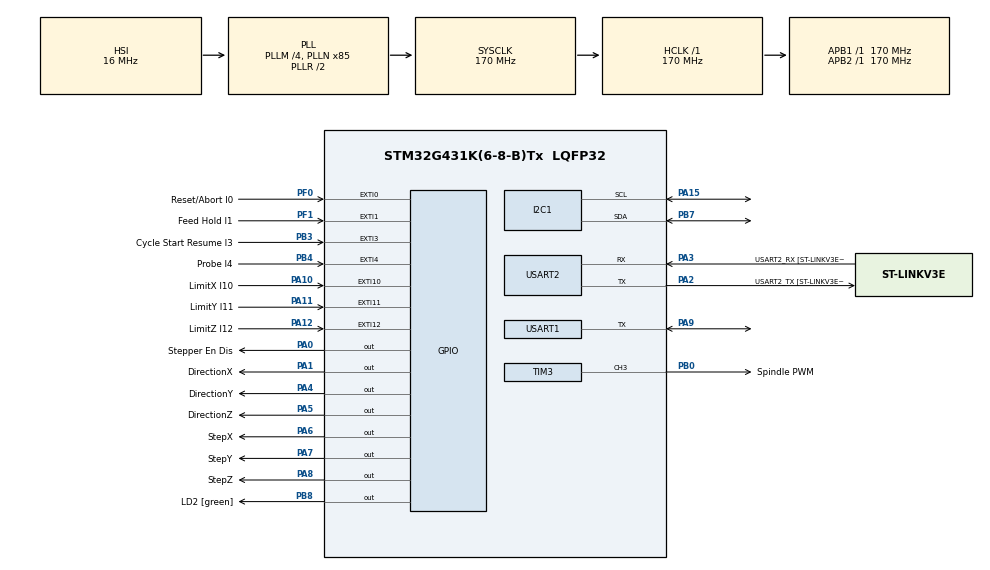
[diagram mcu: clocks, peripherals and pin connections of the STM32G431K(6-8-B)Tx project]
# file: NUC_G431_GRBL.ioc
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Dma.Request0=USART2_TX
Dma.USART2_TX.0.Direction=DMA_MEMORY_TO_PERIPH
Dma.USART2_TX.0.EventEnable=DISABLE
Dma.USART2_TX.0.Instance=DMA1_Channel2
Dma.USART2_TX.0.MemDataAlignment=DMA_MDATAALIGN_BYTE
Dma.USART2_TX.0.MemInc=DMA_MINC_ENABLE
Dma.USART2_TX.0.Mode=DMA_CIRCULAR
Dma.USART2_TX.0.PeriphDataAlignment=DMA_PDATAALIGN_BYTE
Dma.USART2_TX.0.PeriphInc=DMA_PINC_DISABLE
Dma.USART2_TX.0.Polarity=HAL_DMAMUX_REQ_GEN_RISING
Dma.USART2_TX.0.Priority=DMA_PRIORITY_LOW
Dma.USART2_TX.0.RequestNumber=1
Dma.USART2_TX.0.SignalID=NONE
Dma.USART2_TX.0.SyncEnable=DISABLE
Dma.USART2_TX.0.SyncPolarity=HAL_DMAMUX_SYNC_NO_EVENT
Dma.USART2_TX.0.SyncRequestNumber=1
Dma.USART2_TX.0.SyncSignalID=NONE
I2C1.Analog_Filter=I2C_ANALOGFILTER_ENABLE
I2C1.CustomTiming=Disabled
I2C1.I2C_Coeff_DF=0
I2C1.I2C_Fall_Time=0
I2C1.I2C_Rise_Time=0
I2C1.Speed=100
I2C1.Timing=0x30A0A7FB
Mcu.Family=STM32G4
Mcu.Name=STM32G431K(6-8-B)Tx
Mcu.Package=LQFP32
NVIC.DMA1_Channel2_IRQn=true\:0\:0\:false\:false\:true\:false\:true\:true
NVIC.EXTI0_IRQn=true\:0\:0\:false\:false\:true\:true\:true\:true
NVIC.EXTI15_10_IRQn=true\:0\:0\:false\:false\:true\:true\:true\:true
NVIC.EXTI1_IRQn=true\:0\:0\:false\:false\:true\:true\:true\:true
NVIC.EXTI3_IRQn=true\:0\:0\:false\:false\:true\:true\:true\:true
NVIC.EXTI4_IRQn=true\:0\:0\:false\:false\:true\:true\:true\:true
NVIC.PriorityGroup=NVIC_PRIORITYGROUP_4
NVIC.TIM2_IRQn=true\:0\:0\:false\:false\:true\:true\:true\:true
NVIC.TIM4_IRQn=true\:0\:0\:false\:false\:true\:true\:true\:true
NVIC.USART2_IRQn=true\:0\:0\:false\:false\:true\:true\:true\:true
PA0.GPIO_Label=Stepper En Dis
PA0.Signal=GPIO_Output
PA1.GPIO_Label=DirectionX 
PA1.Signal=GPIO_Output
PA10.GPIO_Label=LimitX I10
PA10.GPIO_ModeDefaultEXTI=GPIO_MODE_IT_FALLING
PA10.GPIO_PuPd=GPIO_PULLUP
PA10.Signal=GPXTI10
PA11.GPIO_Label=LimitY I11
PA11.GPIO_ModeDefaultEXTI=GPIO_MODE_IT_FALLING
PA11.GPIO_PuPd=GPIO_PULLUP
PA11.Signal=GPXTI11
PA12.GPIO_Label=LimitZ I12
PA12.GPIO_ModeDefaultEXTI=GPIO_MODE_IT_FALLING
PA12.GPIO_PuPd=GPIO_PULLUP
PA12.Signal=GPXTI12
PA13.GPIO_Label=T_SWDIO
PA13.Mode=Serial_Wire
PA13.Signal=SYS_JTMS-SWDIO
PA14.GPIO_Label=T_SWCLK
PA14.Mode=Serial_Wire
PA14.Signal=SYS_JTCK-SWCLK
PA15.GPIO_Pu=GPIO_PULLUP
PA15.Mode=I2C
PA15.Signal=I2C1_SCL
PA2.GPIO_Label=USART2_TX [ST-LINKV3E_VCP_RX]
PA2.Mode=Asynchronous
PA2.Signal=USART2_TX
PA3.GPIO_Label=USART2_RX [ST-LINKV3E_VCP_TX]
PA3.Mode=Asynchronous
PA3.Signal=USART2_RX
PA4.GPIO_Label=DirectionY
PA4.Signal=GPIO_Output
PA5.GPIO_Label=DirectionZ
PA5.Signal=GPIO_Output
PA6.GPIO_Label=StepX
PA6.Signal=GPIO_Output
PA7.GPIO_Label=StepY
PA7.Signal=GPIO_Output
PA8.GPIO_Label=StepZ
PA8.Signal=GPIO_Output
PA9.Mode=Half_duplex(single_wire_mode)
PA9.Signal=USART1_TX
PB0.GPIO_Label=Spindle PWM
PB0.Signal=S_TIM3_CH3
PB3.GPIO_Label=Cycle Start Resume I3
PB3.GPIO_ModeDefaultEXTI=GPIO_MODE_IT_FALLING
PB3.GPIO_PuPd=GPIO_PULLUP
PB3.Signal=GPXTI3
PB4.GPIO_Label=Probe I4
PB4.GPIO_ModeDefaultEXTI=GPIO_MODE_IT_FALLING
PB4.GPIO_PuPd=GPIO_PULLUP
PB4.Signal=GPXTI4
PB7.GPIO_Pu=GPIO_PULLUP
PB7.Mode=I2C
PB7.Signal=I2C1_SDA
PB8-BOOT0.GPIO_Label=LD2 [green]
PB8-BOOT0.Signal=GPIO_Output
PF0-OSC_IN.GPIO_Label=Reset/Abort I0
PF0-OSC_IN.GPIO_ModeDefaultEXTI=GPIO_MODE_IT_FALLING
PF0-OSC_IN.GPIO_PuPd=GPIO_PULLUP
PF0-OSC_IN.Signal=GPXTI0
PF1-OSC_OUT.GPIO_Label=Feed Hold I1
PF1-OSC_OUT.GPIO_ModeDefaultEXTI=GPIO_MODE_IT_FALLING
PF1-OSC_OUT.GPIO_PuPd=GPIO_PULLUP
PF1-OSC_OUT.Signal=GPXTI1
ProjectManager.HeapSize=0x200
ProjectManager.StackSize=0x400
ProjectManager.TargetToolchain=Makefile
RCC.ADC12Freq_Value=170000000
RCC.AHBFreq_Value=170000000
RCC.APB1Freq_Value=170000000
RCC.APB1TimFreq_Value=170000000
RCC.APB2Freq_Value=170000000
RCC.APB2TimFreq_Value=170000000
RCC.CortexFreq_Value=170000000
RCC.EXTERNAL_CLOCK_VALUE=12288000
RCC.HCLKFreq_Value=170000000
RCC.HSE_VALUE=8000000
RCC.HSI48_VALUE=48000000
RCC.HSI_VALUE=16000000
RCC.LSE_VALUE=32768
RCC.PLLM=RCC_PLLM_DIV4
RCC.PLLN=85
RCC.SYSCLKFreq_VALUE=170000000
RCC.SYSCLKSource=RCC_SYSCLKSOURCE_PLLCLK
RCC.USBFreq_Value=170000000
RCC.VCOOutputFreq_Value=340000000
SH.S_TIM3_CH3.0=TIM3_CH3,PWM Generation3 CH3
TIM2.AutoReloadPreload=TIM_AUTORELOAD_PRELOAD_ENABLE
TIM2.Dithering=Disable
TIM2.PeriodNoDither=100
TIM2.Prescaler=16
TIM3.AutoReloadPreload=TIM_AUTORELOAD_PRELOAD_ENABLE
TIM3.Channel-PWM\ Generation3\ CH3=TIM_CHANNEL_3
TIM3.PeriodNoDither=1000
TIM3.Prescaler=169
TIM3.PulseNoDither_3=5000
TIM4.AutoReloadPreload=TIM_AUTORELOAD_PRELOAD_ENABLE
TIM4.PeriodNoDither=1000
TIM4.Prescaler=169
USART1.VirtualMode-Half_duplex(single_wire_mode)=VM_ASYNC
USART2.VirtualMode-Asynchronous=VM_ASYNC
USART2.WordLength=WORDLENGTH_8B
VP_TIM2_VS_ClockSourceINT.Mode=Internal
VP_TIM3_VS_ClockSourceINT.Mode=Internal
VP_TIM4_VS_ClockSourceINT.Mode=Internal
board=NUCLEO-G431KB

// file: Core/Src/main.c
/* USER CODE BEGIN Header */
/**
 ******************************************************************************
 * @file           : main.c
 * @brief          : Main program body
 ******************************************************************************
 * @attention
 *
 * Copyright (c) 2023 STMicroelectronics.
 * All rights reserved.
 *
 * This software is licensed under terms that can be found in the LICENSE file
 * in the root directory of this software component.
 * If no LICENSE file comes with this software, it is provided AS-IS.
 *
 ******************************************************************************
 */
/* USER CODE END Header */
#include "main.h"
#include "dma.h"
#include "i2c.h"
#include "tim.h"
#include "usart.h"
#include "gpio.h"

void SystemClock_Config(void);

int main(void)
{

  /* MCU Configuration--------------------------------------------------------*/

  /* Reset of all peripherals, Initializes the Flash interface and the Systick. */
  HAL_Init();

  /* Configure the system clock */
  SystemClock_Config();

  /* Initialize all configured peripherals */
  MX_GPIO_Init();
  MX_DMA_Init();
  MX_TIM3_Init();
  MX_USART1_UART_Init();
  MX_USART2_UART_Init();
  MX_I2C1_Init();
  MX_TIM2_Init();
  MX_TIM4_Init();
  /* USER CODE BEGIN 2 */
    extern void main_();
    main_();
  /* USER CODE END 2 */

  /* Infinite loop */
  /* USER CODE BEGIN WHILE */
    while(1) {
        HAL_UART_Transmit(&huart2, "0123456789", 10, 100);
    /* USER CODE END WHILE */

    }
}

void SystemClock_Config(void)
{
  RCC_OscInitTypeDef RCC_OscInitStruct = {0};
  RCC_ClkInitTypeDef RCC_ClkInitStruct = {0};

  /** Configure the main internal regulator output voltage
  */
  HAL_PWREx_ControlVoltageScaling(PWR_REGULATOR_VOLTAGE_SCALE1_BOOST);

  /** Initializes the RCC Oscillators according to the specified parameters
  * in the RCC_OscInitTypeDef structure.
  */
  RCC_OscInitStruct.OscillatorType = RCC_OSCILLATORTYPE_HSI;
  RCC_OscInitStruct.HSIState = RCC_HSI_ON;
  RCC_OscInitStruct.HSICalibrationValue = RCC_HSICALIBRATION_DEFAULT;
  RCC_OscInitStruct.PLL.PLLState = RCC_PLL_ON;
  RCC_OscInitStruct.PLL.PLLSource = RCC_PLLSOURCE_HSI;
  RCC_OscInitStruct.PLL.PLLM = RCC_PLLM_DIV4;
  RCC_OscInitStruct.PLL.PLLN = 85;
  RCC_OscInitStruct.PLL.PLLP = RCC_PLLP_DIV2;
  RCC_OscInitStruct.PLL.PLLQ = RCC_PLLQ_DIV2;
  RCC_OscInitStruct.PLL.PLLR = RCC_PLLR_DIV2;
  if (HAL_RCC_OscConfig(&RCC_OscInitStruct) != HAL_OK)
  {
    Error_Handler();
  }

  /** Initializes the CPU, AHB and APB buses clocks
  */
  RCC_ClkInitStruct.ClockType = RCC_CLOCKTYPE_HCLK|RCC_CLOCKTYPE_SYSCLK
                              |RCC_CLOCKTYPE_PCLK1|RCC_CLOCKTYPE_PCLK2;
  RCC_ClkInitStruct.SYSCLKSource = RCC_SYSCLKSOURCE_PLLCLK;
  RCC_ClkInitStruct.AHBCLKDivider = RCC_SYSCLK_DIV1;
  RCC_ClkInitStruct.APB1CLKDivider = RCC_HCLK_DIV1;
  RCC_ClkInitStruct.APB2CLKDivider = RCC_HCLK_DIV1;

  if (HAL_RCC_ClockConfig(&RCC_ClkInitStruct, FLASH_LATENCY_4) != HAL_OK)
  {
    Error_Handler();
  }
}

void Error_Handler(void)
{
    __disable_irq();
    while(1) {
    }
}
